# RL6842_IP_SVD register map
Vendor: Realtek
Registers are 32-bit, read-write, reset 0x0 unless marked. A register's access mark holds for its fields unless they carry their own. Offsets are from the block's base; [hi:lo] are bit positions; lines under a group give offsets from that group; {n}, {i} and the like mark numbered series.

## PINMUX_REG
Base 0x4100C800
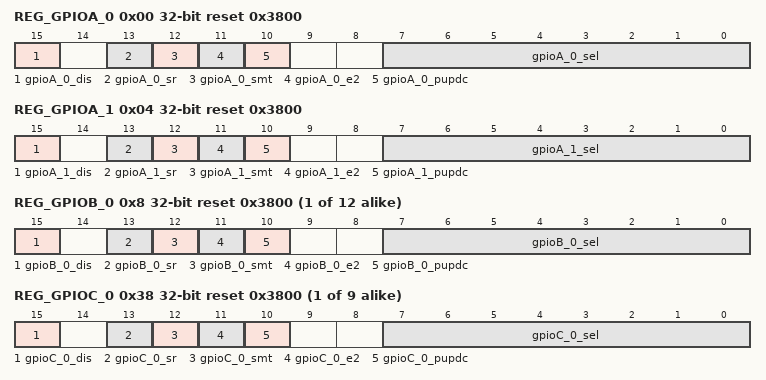
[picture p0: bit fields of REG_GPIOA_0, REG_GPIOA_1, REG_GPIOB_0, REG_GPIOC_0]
0x00 REG_GPIOA_0 reset 0x3800
  [15] gpioA_0_dis — PAD shutdown, only when the whole group's dis signals are all 1, the PAD SHDN will pull down to shutdown the group pad. 1. disable pad 0. enable pad
  [13] gpioA_0_sr — PAD srew rate control
  [12] gpioA_0_smt — PAD Schmit control
  [11] gpioA_0_e2 — PAD driving ability control. 0: low 1: high The actual driving current is depend on pad type.
  [10] gpioA_0_pupdc — Some pad may have two type of PU/PD resistor, this bit can select it. 1: small resistor 0: big resistor
  [7:0] gpioA_0_sel — PAD pinmux function ID selection
0x04 REG_GPIOA_1 reset 0x3800
  [15] gpioA_1_dis — PAD shutdown, only when the whole group's dis signals are all 1, the PAD SHDN will pull down to shutdown the group pad. 1. disable pad 0. enable pad
  [13] gpioA_1_sr — PAD srew rate control
  [12] gpioA_1_smt — PAD Schmit control
  [11] gpioA_1_e2 — PAD driving ability control. 0: low 1: high The actual driving current is depend on pad type.
  [10] gpioA_1_pupdc — Some pad may have two type of PU/PD resistor, this bit can select it. 1: small resistor 0: big resistor
  [7:0] gpioA_1_sel — PAD pinmux function ID selection
{0x8+4i} REG_GPIOB_{i} reset 0x3800 (i=0..11)
  [15] gpioB_{i}_dis — PAD shutdown, only when the whole group's dis signals are all 1, the PAD SHDN will pull down to shutdown the group pad. 1. disable pad 0. enable pad
  [13] gpioB_{i}_sr — PAD srew rate control
  [12] gpioB_{i}_smt — PAD Schmit control
  [11] gpioB_{i}_e2 — PAD driving ability control. 0: low 1: high The actual driving current is depend on pad type.
  [10] gpioB_{i}_pupdc — Some pad may have two type of PU/PD resistor, this bit can select it. 1: small resistor 0: big resistor
  [7:0] gpioB_{i}_sel — PAD pinmux function ID selection
{0x38+4i} REG_GPIOC_{i} reset 0x3800 (i=0..8)
  [15] gpioC_{i}_dis — PAD shutdown, only when the whole group's dis signals are all 1, the PAD SHDN will pull down to shutdown the group pad. 1. disable pad 0. enable pad
  [13] gpioC_{i}_sr — PAD srew rate control
  [12] gpioC_{i}_smt — PAD Schmit control
  [11] gpioC_{i}_e2 — PAD driving ability control. 0: low 1: high The actual driving current is depend on pad type.
  [10] gpioC_{i}_pupdc — Some pad may have two type of PU/PD resistor, this bit can select it. 1: small resistor 0: big resistor
  [7:0] gpioC_{i}_sel — PAD pinmux function ID selection
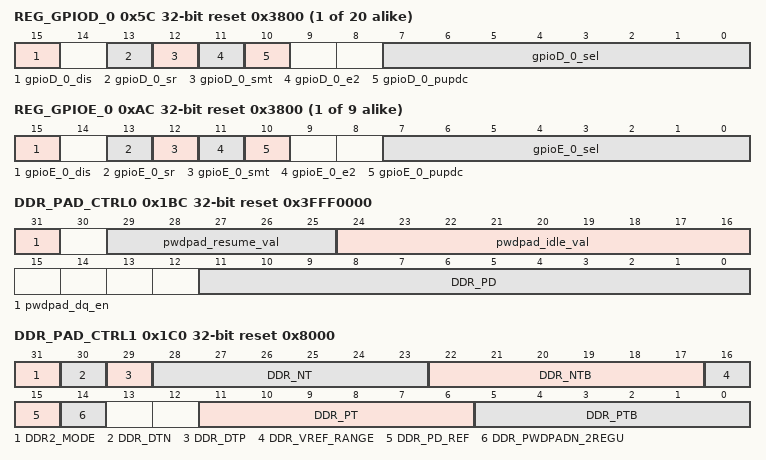
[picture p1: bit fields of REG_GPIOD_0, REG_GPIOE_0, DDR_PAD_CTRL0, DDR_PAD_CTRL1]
{0x5C+4i} REG_GPIOD_{i} reset 0x3800 (i=0..19)
  [15] gpioD_{i}_dis — PAD shutdown, only when the whole group's dis signals are all 1, the PAD SHDN will pull down to shutdown the group pad. 1. disable pad 0. enable pad
  [13] gpioD_{i}_sr — PAD srew rate control
  [12] gpioD_{i}_smt — PAD Schmit control
  [11] gpioD_{i}_e2 — PAD driving ability control. 0: low 1: high The actual driving current is depend on pad type.
  [10] gpioD_{i}_pupdc — Some pad may have two type of PU/PD resistor, this bit can select it. 1: small resistor 0: big resistor
  [7:0] gpioD_{i}_sel — PAD pinmux function ID selection
{0xAC+4i} REG_GPIOE_{i} reset 0x3800 (i=0..8)
  [15] gpioE_{i}_dis — PAD shutdown, only when the whole group's dis signals are all 1, the PAD SHDN will pull down to shutdown the group pad. 1. disable pad 0. enable pad
  [13] gpioE_{i}_sr — PAD srew rate control
  [12] gpioE_{i}_smt — PAD Schmit control
  [11] gpioE_{i}_e2 — PAD driving ability control. 0: low 1: high The actual driving current is depend on pad type.
  [10] gpioE_{i}_pupdc — Some pad may have two type of PU/PD resistor, this bit can select it. 1: small resistor 0: big resistor
  [7:0] gpioE_{i}_sel — PAD pinmux function ID selection
0x100 REG_PU_1 reset 0x100013
  [31:0] pa_pu — PAD pull up enable when system is in active.
0x104 REG_PU_2
  [19:0] pb_pu — PAD pull up enable when system is in active.
0x108 REG_PD_1
  [31:0] pa_pd — PAD pull down enable when system is in active.
0x10C REG_PD_2
  [19:0] pb_pd — PAD pull down enable when system is in active.
0x110 REG_PU_SLP_1
  [31:0] pa_pu_slp — PAD pull up enable when system is in sleep.
0x114 REG_PU_SLP_2
  [19:0] pb_pu_slp — PAD pull up enable when system is in sleep.
0x118 REG_PD_SLP_1
  [31:0] pa_pd_slp — PAD pull down enable when system is in sleep.
0x11C REG_PD_SLP_2
  [19:0] pb_pd_slp — PAD pull down enable when system is in sleep.
0x120 PAD_REG_DUMMY_1 reset 0xFFFF
  [31:0] dummy — HW used only , these are for reserved.
0x1BC DDR_PAD_CTRL0 reset 0x3FFF0000
  [31] pwdpad_dq_en — enable to shutdown dq pads when idle, for psram must be set after configuring pwdpad_idle_val Note: only stop psram auto axi access, manually enable/disable this bit when using psram user axi access
  [29:25] pwdpad_resume_val — dq pads resume counter setting, only for psram, auto axi access will be stopped until resume done
  [24:16] pwdpad_idle_val — idle counter setting, only for psram, shutdown dq pads after reaching this value, must > 0
  [11:0] DDR_PD — Power-down mode, reserved pin
0x1C0 DDR_PAD_CTRL1 reset 0x8000
  [31] DDR2_MODE — DDR2 mode control, set '1' for DDR2 mode
  [30] DDR_DTN — Input duty fine tuning
  [29] DDR_DTP — Input duty fine tuning
  [28:23] DDR_NT — IO output NMOS driving select: active-high, set '1' to increase output N driving capability
  [22:17] DDR_NTB — IOB output NMOS driving select: active-high, set '1' to increase output N driving capability
  [16] DDR_VREF_RANGE — VREF range selector, 0 : 38%~53%, 1 : 44%~59%
  [15] DDR_PD_REF — Power-down mode: active-high, set '1' to disable REF and VREF_DLSS
  [14] DDR_PWDPADN_2REGU — Core power down mode control, need level shift to 3.3V Set "0" for core power down mode and disable all level shifters Set "1" for normal operating condition.
  [11:6] DDR_PT — IO output PMOS driving select: active-high, set '1' to increase output P driving capability
  [5:0] DDR_PTB — IOB output PMOS driving select: active-high, set '1' to increase output P driving capability
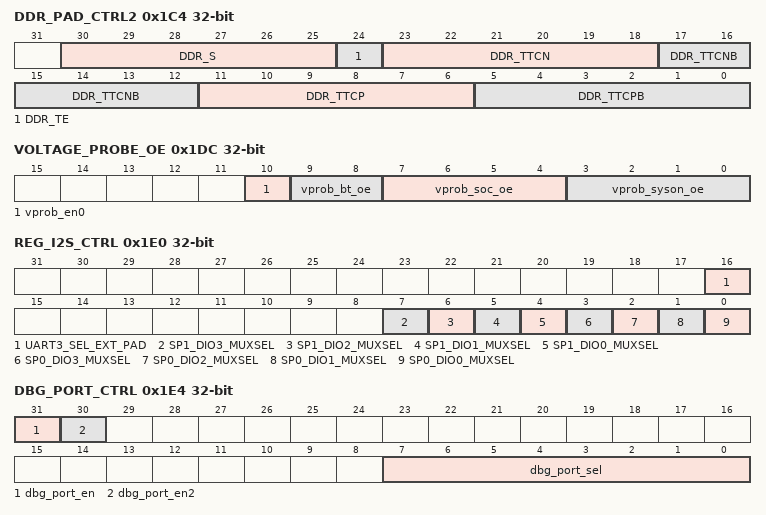
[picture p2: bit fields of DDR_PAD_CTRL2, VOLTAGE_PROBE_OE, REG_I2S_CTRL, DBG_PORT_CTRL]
0x1C4 DDR_PAD_CTRL2
  [30:25] DDR_S — REF voltage fine-tune, add 1% for 1 bit, total 15 bit
  [24] DDR_TE — Termination resistor enable: active-high, set '1' to enable ODT when "E" is '0'.
  [23:18] DDR_TTCN — IO N-ODT coarse trimming: active-high
  [17:12] DDR_TTCNB — IOB N-ODT coarse trimming: active-high
  [11:6] DDR_TTCP — IO P-ODT coarse trimming: active-high
  [5:0] DDR_TTCPB — IOB P-ODT coarse trimming: active-high
0x1D8 PAD_AUD_PAD_CTRL
  [8:0] gpioe_ie — Audio share pad input enable.
0x1DC VOLTAGE_PROBE_OE
  [10] vprob_en0, [9:8] vprob_bt_oe, [7:4] vprob_soc_oe, [3:0] vprob_syson_oe
0x1E0 REG_I2S_CTRL
  [16] UART3_SEL_EXT_PAD — NOTE:this bit reserved, UART3 selection controlled by 0x4100C280.bit[19].
  [7] SP1_DIO3_MUXSEL — SPORT1 DIO3 function mux 0: DIN_3 func 1: DOUT_0 func
  [6] SP1_DIO2_MUXSEL — SPORT1 DIO2 function mux 0: DIN_2 func 1: DOUT_1 func
  [5] SP1_DIO1_MUXSEL — SPORT1 DIO1 function mux 0: DIN_1 func 1: DOUT_2 func
  [4] SP1_DIO0_MUXSEL — SPORT1 DIO0 function mux 0: DIN_0 func 1: DOUT_3 func
  [3] SP0_DIO3_MUXSEL — SPORT0 DIO3 function mux 0: DIN_3 func 1: DOUT_0 func
  [2] SP0_DIO2_MUXSEL — SPORT0 DIO2 function mux 0: DIN_2 func 1: DOUT_1 func
  [1] SP0_DIO1_MUXSEL — SPORT0 DIO1 function mux 0: DIN_1 func 1: DOUT_2 func
  [0] SP0_DIO0_MUXSEL — SPORT0 DIO0 function mux 0: DIN_0 func 1: DOUT_3 func
0x1E4 DBG_PORT_CTRL
  [31] dbg_port_en, [30] dbg_port_en2, [7:0] dbg_port_sel
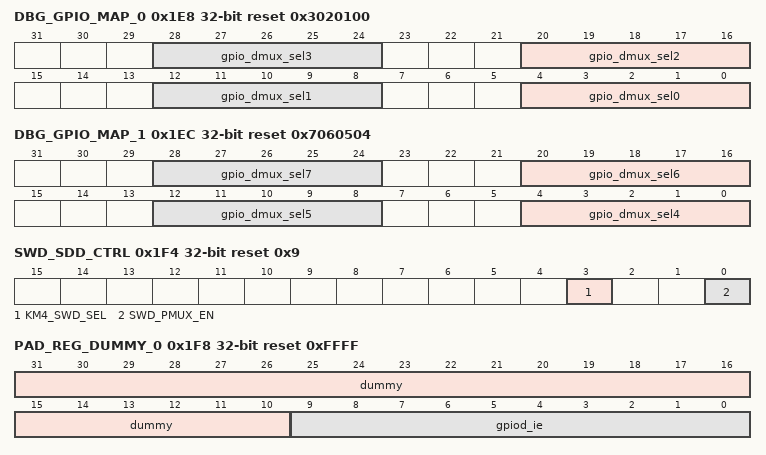
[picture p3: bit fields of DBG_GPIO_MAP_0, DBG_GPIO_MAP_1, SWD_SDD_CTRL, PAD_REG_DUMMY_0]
0x1E8 DBG_GPIO_MAP_0 reset 0x3020100
  [8n+4:8n] gpio_dmux_sel{n} (n=0..3)
0x1EC DBG_GPIO_MAP_1 reset 0x7060504
  [8n-28:8n-32] gpio_dmux_sel{n} (n=4..7)
0x1F0 PINMUX_SUB_CTRL
  [7:5] aux_test_submode — 000: aux adc test 001: flash pll 010: debug clock and power
0x1F4 SWD_SDD_CTRL reset 0x9
  [3] KM4_SWD_SEL — select the share swd signal to KM4 connection write the inverse value to take effect
  [0] SWD_PMUX_EN — 1: Force enable share SWD pinmux function 0: Disable
0x1F8 PAD_REG_DUMMY_0 reset 0xFFFF
  [31:10] dummy — HW used only , these are for reserved.
  [9:0] gpiod_ie — ECO:GPIOD5~14 IE signals
